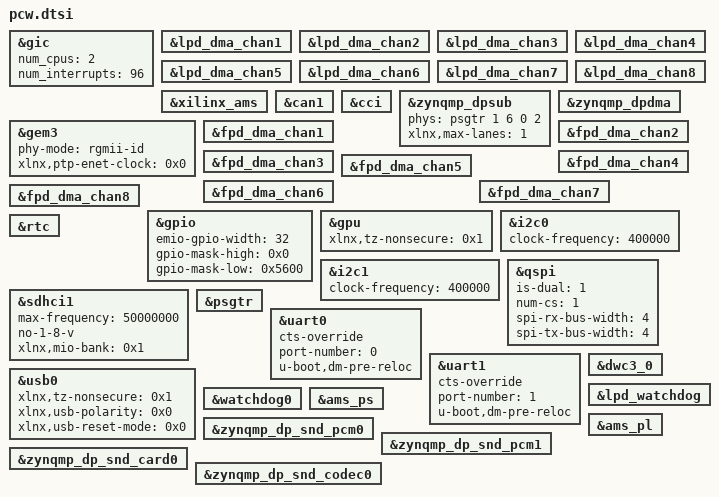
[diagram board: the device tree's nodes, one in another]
/*
 * CAUTION: This file is automatically generated by Xilinx.
 * Version: XSCT 2021.1
 * Today is: Mon Nov 15 09:07:39 2021
 */


&gic {
	num_cpus = <2>;
	num_interrupts = <96>;
};
&lpd_dma_chan1 {
	status = "okay";
};
&lpd_dma_chan2 {
	status = "okay";
};
&lpd_dma_chan3 {
	status = "okay";
};
&lpd_dma_chan4 {
	status = "okay";
};
&lpd_dma_chan5 {
	status = "okay";
};
&lpd_dma_chan6 {
	status = "okay";
};
&lpd_dma_chan7 {
	status = "okay";
};
&lpd_dma_chan8 {
	status = "okay";
};
&xilinx_ams {
	status = "okay";
};
&can1 {
	status = "okay";
};
&cci {
	status = "okay";
};
&zynqmp_dpsub {
	phy-names = "dp-phy0";
	phys = <&psgtr 1 6 0 2>;
	status = "okay";
	xlnx,max-lanes = <1>;
};
&zynqmp_dpdma {
	status = "okay";
};
&gem3 {
	phy-mode = "rgmii-id";
	status = "okay";
	xlnx,ptp-enet-clock = <0x0>;
};
&fpd_dma_chan1 {
	status = "okay";
};
&fpd_dma_chan2 {
	status = "okay";
};
&fpd_dma_chan3 {
	status = "okay";
};
&fpd_dma_chan4 {
	status = "okay";
};
&fpd_dma_chan5 {
	status = "okay";
};
&fpd_dma_chan6 {
	status = "okay";
};
&fpd_dma_chan7 {
	status = "okay";
};
&fpd_dma_chan8 {
	status = "okay";
};
&gpio {
	emio-gpio-width = <32>;
	gpio-mask-high = <0x0>;
	gpio-mask-low = <0x5600>;
	status = "okay";
};
&gpu {
	status = "okay";
	xlnx,tz-nonsecure = <0x1>;
};
&i2c0 {
	clock-frequency = <400000>;
	status = "okay";
};
&i2c1 {
	clock-frequency = <400000>;
	status = "okay";
};
&qspi {
	is-dual = <1>;
	num-cs = <1>;
	spi-rx-bus-width = <4>;
	spi-tx-bus-width = <4>;
	status = "okay";
};
&rtc {
	status = "okay";
};
&sdhci1 {
	max-frequency = <50000000>;
	status = "okay";
	no-1-8-v;
	xlnx,mio-bank = <0x1>;
};
&psgtr {
	status = "okay";
};
&uart0 {
	cts-override ;
	device_type = "serial";
	port-number = <0>;
	status = "okay";
	u-boot,dm-pre-reloc ;
};
&uart1 {
	cts-override ;
	device_type = "serial";
	port-number = <1>;
	status = "okay";
	u-boot,dm-pre-reloc ;
};
&usb0 {
	status = "okay";
	xlnx,tz-nonsecure = <0x1>;
	xlnx,usb-polarity = <0x0>;
	xlnx,usb-reset-mode = <0x0>;
};
&dwc3_0 {
	status = "okay";
};
&lpd_watchdog {
	status = "okay";
};
&watchdog0 {
	status = "okay";
};
&ams_ps {
	status = "okay";
};
&ams_pl {
	status = "okay";
};
&zynqmp_dp_snd_pcm0 {
	status = "okay";
};
&zynqmp_dp_snd_pcm1 {
	status = "okay";
};
&zynqmp_dp_snd_card0 {
	status = "okay";
};
&zynqmp_dp_snd_codec0 {
	status = "okay";
};
